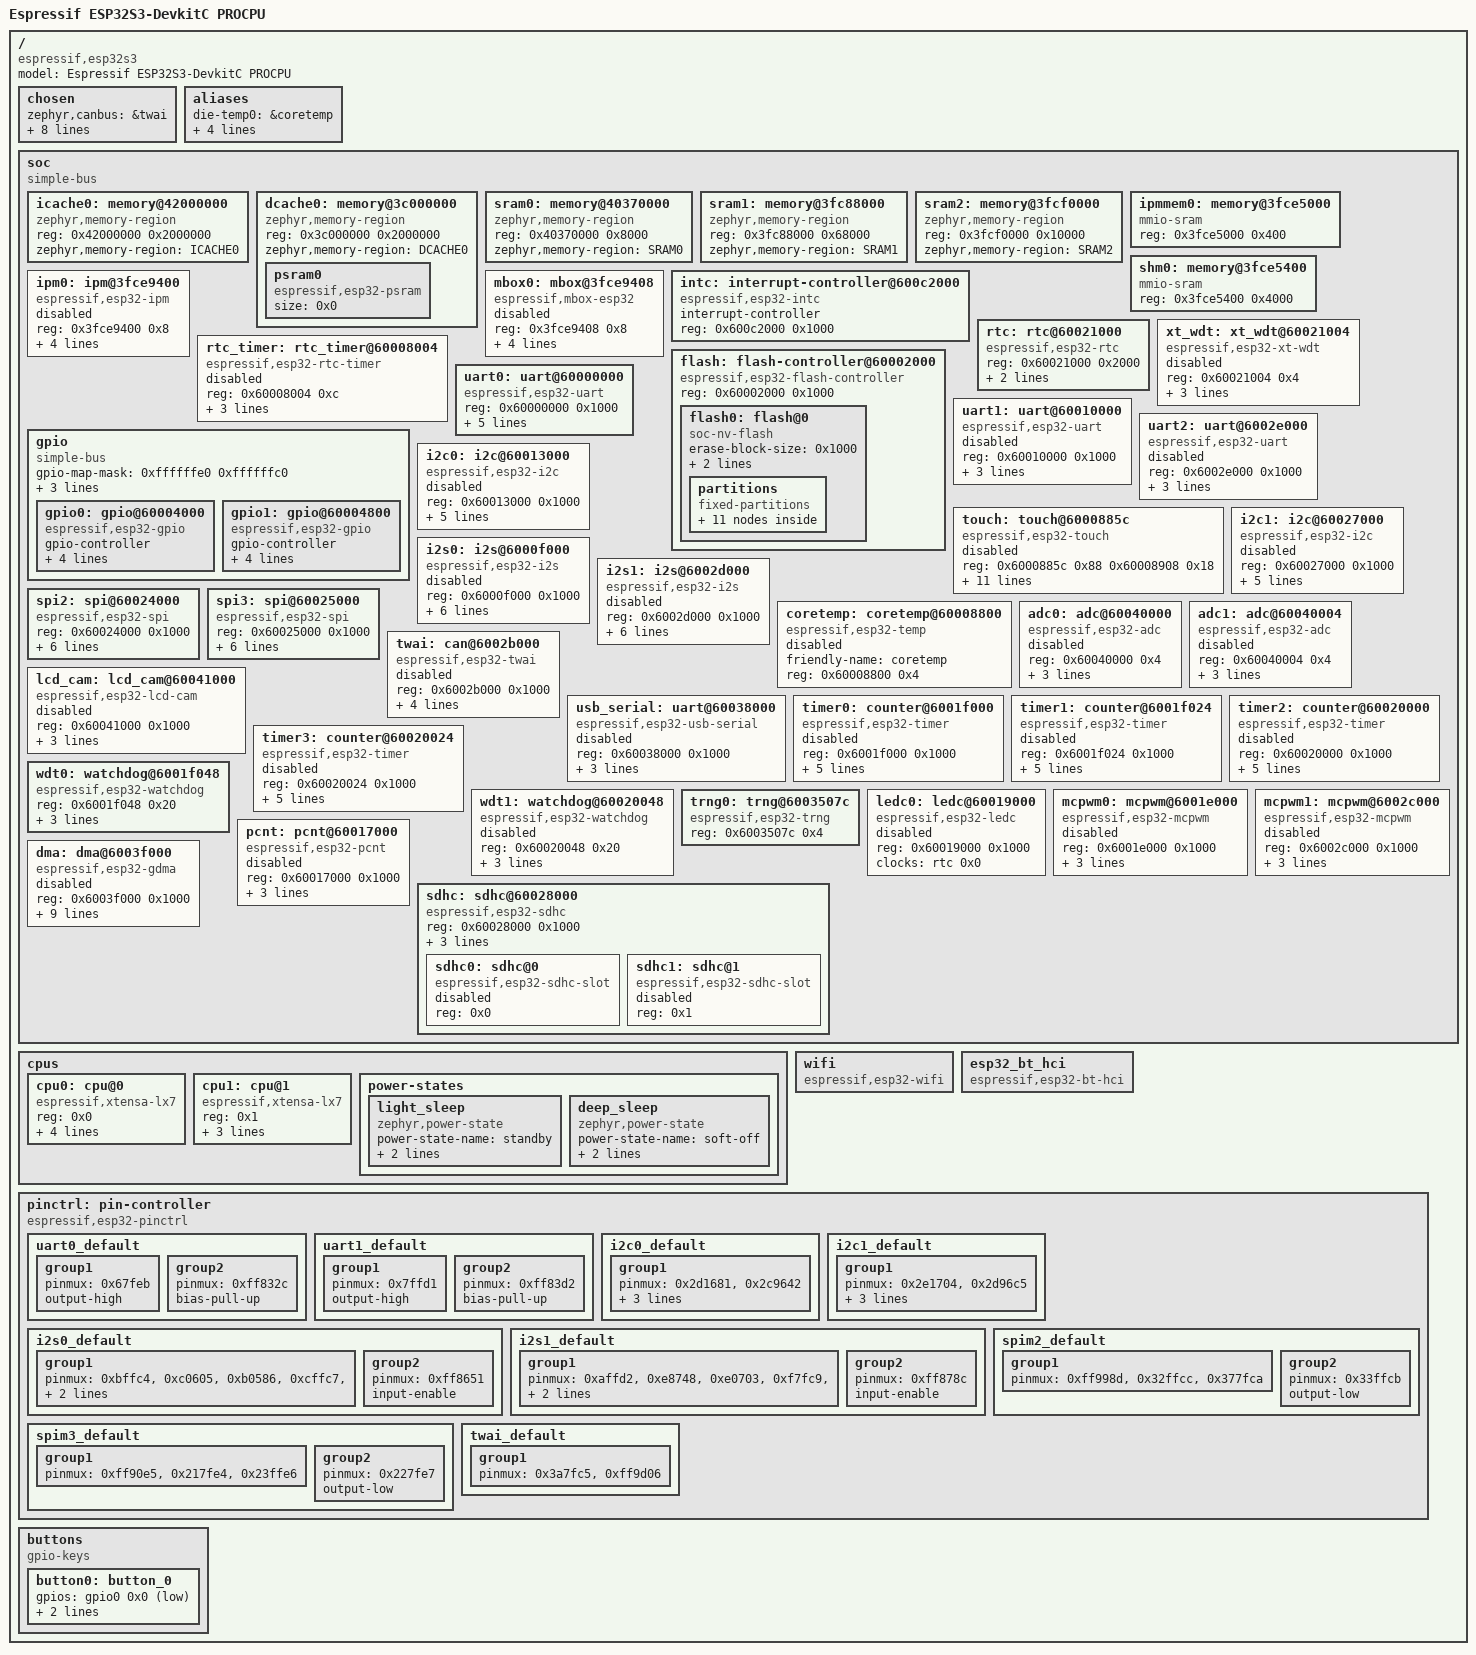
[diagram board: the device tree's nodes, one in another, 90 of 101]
/dts-v1/;

/* node '/' defined in zephyr/dts/common/skeleton.dtsi:9 */
/ {
	#address-cells = < 0x1 >;                   /* in zephyr/dts/common/skeleton.dtsi:10 */
	#size-cells = < 0x1 >;                      /* in zephyr/dts/common/skeleton.dtsi:11 */
	model = "Espressif ESP32S3-DevkitC PROCPU"; /* in zephyr/boards/espressif/esp32s3_devkitc/esp32s3_devkitc_procpu.dts:15 */
	compatible = "espressif,esp32s3";           /* in zephyr/boards/espressif/esp32s3_devkitc/esp32s3_devkitc_procpu.dts:16 */

	/* node '/chosen' defined in zephyr/dts/common/skeleton.dtsi:12 */
	chosen {
		zephyr,canbus = &twai;                    /* in zephyr/dts/xtensa/espressif/esp32s3/esp32s3_common.dtsi:23 */
		zephyr,entropy = &trng0;                  /* in zephyr/dts/xtensa/espressif/esp32s3/esp32s3_common.dtsi:24 */
		zephyr,flash-controller = &flash;         /* in zephyr/dts/xtensa/espressif/esp32s3/esp32s3_common.dtsi:25 */
		zephyr,sram = &sram1;                     /* in zephyr/boards/espressif/esp32s3_devkitc/esp32s3_devkitc_procpu.dts:24 */
		zephyr,console = &uart0;                  /* in zephyr/boards/espressif/esp32s3_devkitc/esp32s3_devkitc_procpu.dts:25 */
		zephyr,shell-uart = &uart0;               /* in zephyr/boards/espressif/esp32s3_devkitc/esp32s3_devkitc_procpu.dts:26 */
		zephyr,flash = &flash0;                   /* in zephyr/boards/espressif/esp32s3_devkitc/esp32s3_devkitc_procpu.dts:27 */
		zephyr,code-partition = &slot0_partition; /* in zephyr/boards/espressif/esp32s3_devkitc/esp32s3_devkitc_procpu.dts:28 */
		zephyr,bt-hci = &esp32_bt_hci;            /* in zephyr/boards/espressif/esp32s3_devkitc/esp32s3_devkitc_procpu.dts:29 */
	};

	/* node '/aliases' defined in zephyr/dts/common/skeleton.dtsi:13 */
	aliases {
		die-temp0 = &coretemp; /* in zephyr/dts/xtensa/espressif/esp32s3/esp32s3_common.dtsi:19 */
		i2c-0 = &i2c0;         /* in zephyr/boards/espressif/esp32s3_devkitc/esp32s3_devkitc_procpu.dts:19 */
		watchdog0 = &wdt0;     /* in zephyr/boards/espressif/esp32s3_devkitc/esp32s3_devkitc_procpu.dts:20 */
		uart-0 = &uart0;       /* in zephyr/boards/espressif/esp32s3_devkitc/esp32s3_devkitc_procpu.dts:33 */
		sw0 = &button0;        /* in zephyr/boards/espressif/esp32s3_devkitc/esp32s3_devkitc_procpu.dts:34 */
	};

	/* node '/soc' defined in zephyr/dts/xtensa/xtensa.dtsi:10 */
	soc {
		#address-cells = < 0x1 >;  /* in zephyr/dts/xtensa/espressif/esp32s3/esp32s3_common.dtsi:84 */
		#size-cells = < 0x1 >;     /* in zephyr/dts/xtensa/espressif/esp32s3/esp32s3_common.dtsi:85 */
		compatible = "simple-bus"; /* in zephyr/dts/xtensa/espressif/esp32s3/esp32s3_common.dtsi:86 */
		ranges;                    /* in zephyr/dts/xtensa/espressif/esp32s3/esp32s3_common.dtsi:87 */

		/* node '/soc/memory@42000000' defined in zephyr/dts/xtensa/espressif/esp32s3/esp32s3_common.dtsi:89 */
		icache0: memory@42000000 {
			compatible = "zephyr,memory-region"; /* in zephyr/dts/xtensa/espressif/esp32s3/esp32s3_common.dtsi:90 */
			reg = < 0x42000000 0x2000000 >;      /* in zephyr/dts/xtensa/espressif/esp32s3/esp32s3_common.dtsi:91 */
			zephyr,memory-region = "ICACHE0";    /* in zephyr/dts/xtensa/espressif/esp32s3/esp32s3_common.dtsi:92 */
		};

		/* node '/soc/memory@3c000000' defined in zephyr/dts/xtensa/espressif/esp32s3/esp32s3_common.dtsi:95 */
		dcache0: memory@3c000000 {
			compatible = "zephyr,memory-region"; /* in zephyr/dts/xtensa/espressif/esp32s3/esp32s3_common.dtsi:96 */
			reg = < 0x3c000000 0x2000000 >;      /* in zephyr/dts/xtensa/espressif/esp32s3/esp32s3_common.dtsi:97 */
			zephyr,memory-region = "DCACHE0";    /* in zephyr/dts/xtensa/espressif/esp32s3/esp32s3_common.dtsi:98 */

			/* node '/soc/memory@3c000000/psram0' defined in zephyr/dts/xtensa/espressif/esp32s3/esp32s3_common.dtsi:100 */
			psram0: psram0 {
				compatible = "espressif,esp32-psram"; /* in zephyr/dts/xtensa/espressif/esp32s3/esp32s3_common.dtsi:101 */
				size = < 0x0 >;                       /* in zephyr/dts/xtensa/espressif/esp32s3/esp32s3_common.dtsi:102 */
			};
		};

		/* node '/soc/memory@40370000' defined in zephyr/dts/xtensa/espressif/esp32s3/esp32s3_common.dtsi:106 */
		sram0: memory@40370000 {
			compatible = "zephyr,memory-region",
			             "mmio-sram";            /* in zephyr/dts/xtensa/espressif/esp32s3/esp32s3_common.dtsi:107 */
			reg = < 0x40370000 0x8000 >;         /* in zephyr/dts/xtensa/espressif/esp32s3/esp32s3_common.dtsi:108 */
			zephyr,memory-region = "SRAM0";      /* in zephyr/dts/xtensa/espressif/esp32s3/esp32s3_common.dtsi:109 */
		};

		/* node '/soc/memory@3fc88000' defined in zephyr/dts/xtensa/espressif/esp32s3/esp32s3_common.dtsi:112 */
		sram1: memory@3fc88000 {
			compatible = "zephyr,memory-region",
			             "mmio-sram";            /* in zephyr/dts/xtensa/espressif/esp32s3/esp32s3_common.dtsi:113 */
			reg = < 0x3fc88000 0x68000 >;        /* in zephyr/dts/xtensa/espressif/esp32s3/esp32s3_common.dtsi:114 */
			zephyr,memory-region = "SRAM1";      /* in zephyr/dts/xtensa/espressif/esp32s3/esp32s3_common.dtsi:115 */
		};

		/* node '/soc/memory@3fcf0000' defined in zephyr/dts/xtensa/espressif/esp32s3/esp32s3_common.dtsi:118 */
		sram2: memory@3fcf0000 {
			compatible = "zephyr,memory-region",
			             "mmio-sram";            /* in zephyr/dts/xtensa/espressif/esp32s3/esp32s3_common.dtsi:119 */
			reg = < 0x3fcf0000 0x10000 >;        /* in zephyr/dts/xtensa/espressif/esp32s3/esp32s3_common.dtsi:120 */
			zephyr,memory-region = "SRAM2";      /* in zephyr/dts/xtensa/espressif/esp32s3/esp32s3_common.dtsi:121 */
		};

		/* node '/soc/memory@3fce5000' defined in zephyr/dts/xtensa/espressif/esp32s3/esp32s3_common.dtsi:124 */
		ipmmem0: memory@3fce5000 {
			compatible = "mmio-sram";   /* in zephyr/dts/xtensa/espressif/esp32s3/esp32s3_common.dtsi:125 */
			reg = < 0x3fce5000 0x400 >; /* in zephyr/dts/xtensa/espressif/esp32s3/esp32s3_common.dtsi:126 */
			phandle = < 0x1 >;          /* in zephyr/dts/xtensa/espressif/esp32s3/esp32s3_common.dtsi:138 */
		};

		/* node '/soc/memory@3fce5400' defined in zephyr/dts/xtensa/espressif/esp32s3/esp32s3_common.dtsi:129 */
		shm0: memory@3fce5400 {
			compatible = "mmio-sram";    /* in zephyr/dts/xtensa/espressif/esp32s3/esp32s3_common.dtsi:130 */
			reg = < 0x3fce5400 0x4000 >; /* in zephyr/dts/xtensa/espressif/esp32s3/esp32s3_common.dtsi:131 */
		};

		/* node '/soc/ipm@3fce9400' defined in zephyr/dts/xtensa/espressif/esp32s3/esp32s3_common.dtsi:134 */
		ipm0: ipm@3fce9400 {
			compatible = "espressif,esp32-ipm"; /* in zephyr/dts/xtensa/espressif/esp32s3/esp32s3_common.dtsi:135 */
			reg = < 0x3fce9400 0x8 >;           /* in zephyr/dts/xtensa/espressif/esp32s3/esp32s3_common.dtsi:136 */
			status = "disabled";                /* in zephyr/dts/xtensa/espressif/esp32s3/esp32s3_common.dtsi:137 */
			shared-memory = < &ipmmem0 >;       /* in zephyr/dts/xtensa/espressif/esp32s3/esp32s3_common.dtsi:138 */
			shared-memory-size = < 0x400 >;     /* in zephyr/dts/xtensa/espressif/esp32s3/esp32s3_common.dtsi:139 */
			interrupts = < 0x4f 0x0 0x0 >,
			             < 0x50 0x0 0x0 >;      /* in zephyr/dts/xtensa/espressif/esp32s3/esp32s3_common.dtsi:140 */
			interrupt-parent = < &intc >;       /* in zephyr/dts/xtensa/espressif/esp32s3/esp32s3_common.dtsi:143 */
		};

		/* node '/soc/mbox@3fce9408' defined in zephyr/dts/xtensa/espressif/esp32s3/esp32s3_common.dtsi:146 */
		mbox0: mbox@3fce9408 {
			compatible = "espressif,mbox-esp32"; /* in zephyr/dts/xtensa/espressif/esp32s3/esp32s3_common.dtsi:147 */
			reg = < 0x3fce9408 0x8 >;            /* in zephyr/dts/xtensa/espressif/esp32s3/esp32s3_common.dtsi:148 */
			status = "disabled";                 /* in zephyr/dts/xtensa/espressif/esp32s3/esp32s3_common.dtsi:149 */
			shared-memory = < &ipmmem0 >;        /* in zephyr/dts/xtensa/espressif/esp32s3/esp32s3_common.dtsi:150 */
			shared-memory-size = < 0x400 >;      /* in zephyr/dts/xtensa/espressif/esp32s3/esp32s3_common.dtsi:151 */
			interrupts = < 0x4f 0x0 0x0 >,
			             < 0x50 0x0 0x0 >;       /* in zephyr/dts/xtensa/espressif/esp32s3/esp32s3_common.dtsi:152 */
			interrupt-parent = < &intc >;        /* in zephyr/dts/xtensa/espressif/esp32s3/esp32s3_common.dtsi:155 */
			#mbox-cells = < 0x1 >;               /* in zephyr/dts/xtensa/espressif/esp32s3/esp32s3_common.dtsi:156 */
		};

		/* node '/soc/interrupt-controller@600c2000' defined in zephyr/dts/xtensa/espressif/esp32s3/esp32s3_common.dtsi:159 */
		intc: interrupt-controller@600c2000 {
			#interrupt-cells = < 0x3 >;          /* in zephyr/dts/xtensa/espressif/esp32s3/esp32s3_common.dtsi:160 */
			#address-cells = < 0x0 >;            /* in zephyr/dts/xtensa/espressif/esp32s3/esp32s3_common.dtsi:161 */
			compatible = "espressif,esp32-intc"; /* in zephyr/dts/xtensa/espressif/esp32s3/esp32s3_common.dtsi:162 */
			interrupt-controller;                /* in zephyr/dts/xtensa/espressif/esp32s3/esp32s3_common.dtsi:163 */
			reg = < 0x600c2000 0x1000 >;         /* in zephyr/dts/xtensa/espressif/esp32s3/esp32s3_common.dtsi:164 */
			status = "okay";                     /* in zephyr/dts/xtensa/espressif/esp32s3/esp32s3_common.dtsi:165 */
			phandle = < 0x2 >;                   /* in zephyr/dts/xtensa/espressif/esp32s3/esp32s3_common.dtsi:143 */
		};

		/* node '/soc/rtc@60021000' defined in zephyr/dts/xtensa/espressif/esp32s3/esp32s3_common.dtsi:168 */
		rtc: rtc@60021000 {
			compatible = "espressif,esp32-rtc"; /* in zephyr/dts/xtensa/espressif/esp32s3/esp32s3_common.dtsi:169 */
			reg = < 0x60021000 0x2000 >;        /* in zephyr/dts/xtensa/espressif/esp32s3/esp32s3_common.dtsi:170 */
			fast-clk-src = < 0x1 >;             /* in zephyr/dts/xtensa/espressif/esp32s3/esp32s3_common.dtsi:171 */
			slow-clk-src = < 0x0 >;             /* in zephyr/dts/xtensa/espressif/esp32s3/esp32s3_common.dtsi:172 */
			#clock-cells = < 0x1 >;             /* in zephyr/dts/xtensa/espressif/esp32s3/esp32s3_common.dtsi:173 */
			status = "okay";                    /* in zephyr/dts/xtensa/espressif/esp32s3/esp32s3_common.dtsi:174 */
			phandle = < 0x3 >;                  /* in zephyr/dts/xtensa/espressif/esp32s3/esp32s3_common.dtsi:180 */
		};

		/* node '/soc/xt_wdt@60021004' defined in zephyr/dts/xtensa/espressif/esp32s3/esp32s3_common.dtsi:177 */
		xt_wdt: xt_wdt@60021004 {
			compatible = "espressif,esp32-xt-wdt"; /* in zephyr/dts/xtensa/espressif/esp32s3/esp32s3_common.dtsi:178 */
			reg = < 0x60021004 0x4 >;              /* in zephyr/dts/xtensa/espressif/esp32s3/esp32s3_common.dtsi:179 */
			clocks = < &rtc 0x28 >;                /* in zephyr/dts/xtensa/espressif/esp32s3/esp32s3_common.dtsi:180 */
			interrupts = < 0x27 0x0 0x0 >;         /* in zephyr/dts/xtensa/espressif/esp32s3/esp32s3_common.dtsi:181 */
			interrupt-parent = < &intc >;          /* in zephyr/dts/xtensa/espressif/esp32s3/esp32s3_common.dtsi:182 */
			status = "disabled";                   /* in zephyr/dts/xtensa/espressif/esp32s3/esp32s3_common.dtsi:183 */
		};

		/* node '/soc/rtc_timer@60008004' defined in zephyr/dts/xtensa/espressif/esp32s3/esp32s3_common.dtsi:186 */
		rtc_timer: rtc_timer@60008004 {
			reg = < 0x60008004 0xc >;                 /* in zephyr/dts/xtensa/espressif/esp32s3/esp32s3_common.dtsi:187 */
			compatible = "espressif,esp32-rtc-timer"; /* in zephyr/dts/xtensa/espressif/esp32s3/esp32s3_common.dtsi:188 */
			clocks = < &rtc 0x28 >;                   /* in zephyr/dts/xtensa/espressif/esp32s3/esp32s3_common.dtsi:189 */
			interrupts = < 0x27 0x0 0x0 >;            /* in zephyr/dts/xtensa/espressif/esp32s3/esp32s3_common.dtsi:190 */
			interrupt-parent = < &intc >;             /* in zephyr/dts/xtensa/espressif/esp32s3/esp32s3_common.dtsi:191 */
			status = "disabled";                      /* in zephyr/dts/xtensa/espressif/esp32s3/esp32s3_common.dtsi:192 */
		};

		/* node '/soc/flash-controller@60002000' defined in zephyr/dts/xtensa/espressif/esp32s3/esp32s3_common.dtsi:195 */
		flash: flash-controller@60002000 {
			compatible = "espressif,esp32-flash-controller"; /* in zephyr/dts/xtensa/espressif/esp32s3/esp32s3_common.dtsi:196 */
			reg = < 0x60002000 0x1000 >;                     /* in zephyr/dts/xtensa/espressif/esp32s3/esp32s3_common.dtsi:197 */
			#address-cells = < 0x1 >;                        /* in zephyr/dts/xtensa/espressif/esp32s3/esp32s3_common.dtsi:198 */
			#size-cells = < 0x1 >;                           /* in zephyr/dts/xtensa/espressif/esp32s3/esp32s3_common.dtsi:199 */

			/* node '/soc/flash-controller@60002000/flash@0' defined in zephyr/dts/xtensa/espressif/esp32s3/esp32s3_common.dtsi:201 */
			flash0: flash@0 {
				compatible = "soc-nv-flash";   /* in zephyr/dts/xtensa/espressif/esp32s3/esp32s3_common.dtsi:202 */
				erase-block-size = < 0x1000 >; /* in zephyr/dts/xtensa/espressif/esp32s3/esp32s3_common.dtsi:203 */
				write-block-size = < 0x4 >;    /* in zephyr/dts/xtensa/espressif/esp32s3/esp32s3_common.dtsi:204 */
				reg = < 0x0 0x800000 >;        /* in zephyr/dts/xtensa/espressif/esp32s3/esp32s3_wroom_n8.dtsi:11 */

				/* node '/soc/flash-controller@60002000/flash@0/partitions' defined in zephyr/dts/vendor/espressif/partitions_0x0_amp_4M.dtsi:8 */
				partitions {
					compatible = "fixed-partitions"; /* in zephyr/dts/vendor/espressif/partitions_0x0_amp_4M.dtsi:9 */
					#address-cells = < 0x1 >;        /* in zephyr/dts/vendor/espressif/partitions_0x0_amp_4M.dtsi:10 */
					#size-cells = < 0x1 >;           /* in zephyr/dts/vendor/espressif/partitions_0x0_amp_4M.dtsi:11 */

					/* node '/soc/flash-controller@60002000/flash@0/partitions/partition@0' defined in zephyr/dts/vendor/espressif/partitions_0x0_amp_4M.dtsi:13 */
					boot_partition: partition@0 {
						label = "mcuboot";     /* in zephyr/dts/vendor/espressif/partitions_0x0_amp_4M.dtsi:14 */
						reg = < 0x0 0x10000 >; /* in zephyr/dts/vendor/espressif/partitions_0x0_amp_4M.dtsi:15 */
					};

					/* node '/soc/flash-controller@60002000/flash@0/partitions/partition@10000' defined in zephyr/dts/vendor/espressif/partitions_0x0_amp_4M.dtsi:18 */
					sys_partition: partition@10000 {
						label = "sys";             /* in zephyr/dts/vendor/espressif/partitions_0x0_amp_4M.dtsi:19 */
						reg = < 0x10000 0x10000 >; /* in zephyr/dts/vendor/espressif/partitions_0x0_amp_4M.dtsi:20 */
					};

					/* node '/soc/flash-controller@60002000/flash@0/partitions/partition@20000' defined in zephyr/dts/vendor/espressif/partitions_0x0_amp_4M.dtsi:23 */
					slot0_partition: partition@20000 {
						label = "image-0";          /* in zephyr/dts/vendor/espressif/partitions_0x0_amp_4M.dtsi:24 */
						reg = < 0x20000 0x150000 >; /* in zephyr/dts/vendor/espressif/partitions_0x0_amp_4M.dtsi:25 */
					};

					/* node '/soc/flash-controller@60002000/flash@0/partitions/partition@170000' defined in zephyr/dts/vendor/espressif/partitions_0x0_amp_4M.dtsi:28 */
					slot1_partition: partition@170000 {
						label = "image-1";           /* in zephyr/dts/vendor/espressif/partitions_0x0_amp_4M.dtsi:29 */
						reg = < 0x170000 0x150000 >; /* in zephyr/dts/vendor/espressif/partitions_0x0_amp_4M.dtsi:30 */
					};

					/* node '/soc/flash-controller@60002000/flash@0/partitions/partition@2c0000' defined in zephyr/dts/vendor/espressif/partitions_0x0_amp_4M.dtsi:33 */
					slot0_appcpu_partition: partition@2c0000 {
						label = "image-0-appcpu";   /* in zephyr/dts/vendor/espressif/partitions_0x0_amp_4M.dtsi:34 */
						reg = < 0x2c0000 0x70000 >; /* in zephyr/dts/vendor/espressif/partitions_0x0_amp_4M.dtsi:35 */
					};

					/* node '/soc/flash-controller@60002000/flash@0/partitions/partition@330000' defined in zephyr/dts/vendor/espressif/partitions_0x0_amp_4M.dtsi:38 */
					slot1_appcpu_partition: partition@330000 {
						label = "image-1-appcpu";   /* in zephyr/dts/vendor/espressif/partitions_0x0_amp_4M.dtsi:39 */
						reg = < 0x330000 0x70000 >; /* in zephyr/dts/vendor/espressif/partitions_0x0_amp_4M.dtsi:40 */
					};

					/* node '/soc/flash-controller@60002000/flash@0/partitions/partition@3a0000' defined in zephyr/dts/vendor/espressif/partitions_0x0_amp_4M.dtsi:43 */
					slot0_lpcore_partition: partition@3a0000 {
						label = "image-0-lpcore";  /* in zephyr/dts/vendor/espressif/partitions_0x0_amp_4M.dtsi:44 */
						reg = < 0x3a0000 0x8000 >; /* in zephyr/dts/vendor/espressif/partitions_0x0_amp_4M.dtsi:45 */
					};

					/* node '/soc/flash-controller@60002000/flash@0/partitions/partition@3a8000' defined in zephyr/dts/vendor/espressif/partitions_0x0_amp_4M.dtsi:48 */
					slot1_lpcore_partition: partition@3a8000 {
						label = "image-1-lpcore";  /* in zephyr/dts/vendor/espressif/partitions_0x0_amp_4M.dtsi:49 */
						reg = < 0x3a8000 0x8000 >; /* in zephyr/dts/vendor/espressif/partitions_0x0_amp_4M.dtsi:50 */
					};

					/* node '/soc/flash-controller@60002000/flash@0/partitions/partition@3b0000' defined in zephyr/dts/vendor/espressif/partitions_0x0_amp_4M.dtsi:53 */
					storage_partition: partition@3b0000 {
						label = "storage";          /* in zephyr/dts/vendor/espressif/partitions_0x0_amp_4M.dtsi:54 */
						reg = < 0x3b0000 0x30000 >; /* in zephyr/dts/vendor/espressif/partitions_0x0_amp_4M.dtsi:55 */
					};

					/* node '/soc/flash-controller@60002000/flash@0/partitions/partition@3e0000' defined in zephyr/dts/vendor/espressif/partitions_0x0_amp_4M.dtsi:58 */
					scratch_partition: partition@3e0000 {
						label = "image-scratch";    /* in zephyr/dts/vendor/espressif/partitions_0x0_amp_4M.dtsi:59 */
						reg = < 0x3e0000 0x1f000 >; /* in zephyr/dts/vendor/espressif/partitions_0x0_amp_4M.dtsi:60 */
					};

					/* node '/soc/flash-controller@60002000/flash@0/partitions/partition@3ff000' defined in zephyr/dts/vendor/espressif/partitions_0x0_amp_4M.dtsi:63 */
					coredump_partition: partition@3ff000 {
						label = "coredump";        /* in zephyr/dts/vendor/espressif/partitions_0x0_amp_4M.dtsi:64 */
						reg = < 0x3ff000 0x1000 >; /* in zephyr/dts/vendor/espressif/partitions_0x0_amp_4M.dtsi:65 */
					};
				};
			};
		};

		/* node '/soc/uart@60000000' defined in zephyr/dts/xtensa/espressif/esp32s3/esp32s3_common.dtsi:209 */
		uart0: uart@60000000 {
			compatible = "espressif,esp32-uart"; /* in zephyr/dts/xtensa/espressif/esp32s3/esp32s3_common.dtsi:210 */
			reg = < 0x60000000 0x1000 >;         /* in zephyr/dts/xtensa/espressif/esp32s3/esp32s3_common.dtsi:211 */
			interrupts = < 0x1b 0x0 0x0 >;       /* in zephyr/dts/xtensa/espressif/esp32s3/esp32s3_common.dtsi:212 */
			interrupt-parent = < &intc >;        /* in zephyr/dts/xtensa/espressif/esp32s3/esp32s3_common.dtsi:213 */
			clocks = < &rtc 0x1 >;               /* in zephyr/dts/xtensa/espressif/esp32s3/esp32s3_common.dtsi:214 */
			status = "okay";                     /* in zephyr/boards/espressif/esp32s3_devkitc/esp32s3_devkitc_procpu.dts:52 */
			current-speed = < 0x1c200 >;         /* in zephyr/boards/espressif/esp32s3_devkitc/esp32s3_devkitc_procpu.dts:53 */
			pinctrl-0 = < &uart0_default >;      /* in zephyr/boards/espressif/esp32s3_devkitc/esp32s3_devkitc_procpu.dts:54 */
			pinctrl-names = "default";           /* in zephyr/boards/espressif/esp32s3_devkitc/esp32s3_devkitc_procpu.dts:55 */
		};

		/* node '/soc/uart@60010000' defined in zephyr/dts/xtensa/espressif/esp32s3/esp32s3_common.dtsi:218 */
		uart1: uart@60010000 {
			compatible = "espressif,esp32-uart"; /* in zephyr/dts/xtensa/espressif/esp32s3/esp32s3_common.dtsi:219 */
			reg = < 0x60010000 0x1000 >;         /* in zephyr/dts/xtensa/espressif/esp32s3/esp32s3_common.dtsi:220 */
			interrupts = < 0x1c 0x0 0x0 >;       /* in zephyr/dts/xtensa/espressif/esp32s3/esp32s3_common.dtsi:221 */
			interrupt-parent = < &intc >;        /* in zephyr/dts/xtensa/espressif/esp32s3/esp32s3_common.dtsi:222 */
			clocks = < &rtc 0x2 >;               /* in zephyr/dts/xtensa/espressif/esp32s3/esp32s3_common.dtsi:223 */
			status = "disabled";                 /* in zephyr/dts/xtensa/espressif/esp32s3/esp32s3_common.dtsi:224 */
		};

		/* node '/soc/uart@6002e000' defined in zephyr/dts/xtensa/espressif/esp32s3/esp32s3_common.dtsi:227 */
		uart2: uart@6002e000 {
			compatible = "espressif,esp32-uart"; /* in zephyr/dts/xtensa/espressif/esp32s3/esp32s3_common.dtsi:228 */
			reg = < 0x6002e000 0x1000 >;         /* in zephyr/dts/xtensa/espressif/esp32s3/esp32s3_common.dtsi:229 */
			interrupts = < 0x1d 0x0 0x0 >;       /* in zephyr/dts/xtensa/espressif/esp32s3/esp32s3_common.dtsi:230 */
			interrupt-parent = < &intc >;        /* in zephyr/dts/xtensa/espressif/esp32s3/esp32s3_common.dtsi:231 */
			clocks = < &rtc 0x3 >;               /* in zephyr/dts/xtensa/espressif/esp32s3/esp32s3_common.dtsi:232 */
			status = "disabled";                 /* in zephyr/dts/xtensa/espressif/esp32s3/esp32s3_common.dtsi:233 */
		};

		/* node '/soc/gpio' defined in zephyr/dts/xtensa/espressif/esp32s3/esp32s3_common.dtsi:236 */
		gpio: gpio {
			compatible = "simple-bus";                                     /* in zephyr/dts/xtensa/espressif/esp32s3/esp32s3_common.dtsi:237 */
			gpio-map-mask = < 0xffffffe0 0xffffffc0 >;                     /* in zephyr/dts/xtensa/espressif/esp32s3/esp32s3_common.dtsi:238 */
			gpio-map-pass-thru = < 0x1f 0x3f >;                            /* in zephyr/dts/xtensa/espressif/esp32s3/esp32s3_common.dtsi:239 */
			gpio-map = < 0x0 0x0 &gpio0 0x0 0x0 0x20 0x0 &gpio1 0x0 0x0 >; /* in zephyr/dts/xtensa/espressif/esp32s3/esp32s3_common.dtsi:240 */
			#gpio-cells = < 0x2 >;                                         /* in zephyr/dts/xtensa/espressif/esp32s3/esp32s3_common.dtsi:244 */
			#address-cells = < 0x1 >;                                      /* in zephyr/dts/xtensa/espressif/esp32s3/esp32s3_common.dtsi:245 */
			#size-cells = < 0x1 >;                                         /* in zephyr/dts/xtensa/espressif/esp32s3/esp32s3_common.dtsi:246 */
			ranges;                                                        /* in zephyr/dts/xtensa/espressif/esp32s3/esp32s3_common.dtsi:247 */

			/* node '/soc/gpio/gpio@60004000' defined in zephyr/dts/xtensa/espressif/esp32s3/esp32s3_common.dtsi:249 */
			gpio0: gpio@60004000 {
				compatible = "espressif,esp32-gpio"; /* in zephyr/dts/xtensa/espressif/esp32s3/esp32s3_common.dtsi:250 */
				gpio-controller;                     /* in zephyr/dts/xtensa/espressif/esp32s3/esp32s3_common.dtsi:251 */
				#gpio-cells = < 0x2 >;               /* in zephyr/dts/xtensa/espressif/esp32s3/esp32s3_common.dtsi:252 */
				reg = < 0x60004000 0x800 >;          /* in zephyr/dts/xtensa/espressif/esp32s3/esp32s3_common.dtsi:253 */
				interrupts = < 0x10 0x0 0x0 >;       /* in zephyr/dts/xtensa/espressif/esp32s3/esp32s3_common.dtsi:254 */
				interrupt-parent = < &intc >;        /* in zephyr/dts/xtensa/espressif/esp32s3/esp32s3_common.dtsi:255 */
				ngpios = < 0x20 >;                   /* in zephyr/dts/xtensa/espressif/esp32s3/esp32s3_common.dtsi:261 */
				status = "okay";                     /* in zephyr/boards/espressif/esp32s3_devkitc/esp32s3_devkitc_procpu.dts:59 */
				phandle = < 0x5 >;                   /* in zephyr/dts/xtensa/espressif/esp32s3/esp32s3_common.dtsi:240 */
			};

			/* node '/soc/gpio/gpio@60004800' defined in zephyr/dts/xtensa/espressif/esp32s3/esp32s3_common.dtsi:264 */
			gpio1: gpio@60004800 {
				compatible = "espressif,esp32-gpio"; /* in zephyr/dts/xtensa/espressif/esp32s3/esp32s3_common.dtsi:265 */
				gpio-controller;                     /* in zephyr/dts/xtensa/espressif/esp32s3/esp32s3_common.dtsi:266 */
				#gpio-cells = < 0x2 >;               /* in zephyr/dts/xtensa/espressif/esp32s3/esp32s3_common.dtsi:267 */
				reg = < 0x60004800 0x800 >;          /* in zephyr/dts/xtensa/espressif/esp32s3/esp32s3_common.dtsi:268 */
				interrupts = < 0x10 0x0 0x0 >;       /* in zephyr/dts/xtensa/espressif/esp32s3/esp32s3_common.dtsi:269 */
				interrupt-parent = < &intc >;        /* in zephyr/dts/xtensa/espressif/esp32s3/esp32s3_common.dtsi:270 */
				ngpios = < 0x16 >;                   /* in zephyr/dts/xtensa/espressif/esp32s3/esp32s3_common.dtsi:271 */
				status = "okay";                     /* in zephyr/boards/espressif/esp32s3_devkitc/esp32s3_devkitc_procpu.dts:63 */
				phandle = < 0x6 >;                   /* in zephyr/dts/xtensa/espressif/esp32s3/esp32s3_common.dtsi:240 */
			};
		};

		/* node '/soc/touch@6000885c' defined in zephyr/dts/xtensa/espressif/esp32s3/esp32s3_common.dtsi:275 */
		touch: touch@6000885c {
			compatible = "espressif,esp32-touch";      /* in zephyr/dts/xtensa/espressif/esp32s3/esp32s3_common.dtsi:276 */
			reg = < 0x6000885c 0x88 0x60008908 0x18 >; /* in zephyr/dts/xtensa/espressif/esp32s3/esp32s3_common.dtsi:277 */
			interrupts = < 0x27 0x0 0x0 >;             /* in zephyr/dts/xtensa/espressif/esp32s3/esp32s3_common.dtsi:278 */
			interrupt-parent = < &intc >;              /* in zephyr/dts/xtensa/espressif/esp32s3/esp32s3_common.dtsi:279 */
			status = "disabled";                       /* in zephyr/dts/xtensa/espressif/esp32s3/esp32s3_common.dtsi:280 */
			debounce-interval-ms = < 0x1e >;           /* in zephyr/boards/espressif/esp32s3_devkitc/esp32s3_devkitc_procpu.dts:67 */
			href-microvolt = < 0x2932e0 >;             /* in zephyr/boards/espressif/esp32s3_devkitc/esp32s3_devkitc_procpu.dts:68 */
			lref-microvolt = < 0x7a120 >;              /* in zephyr/boards/espressif/esp32s3_devkitc/esp32s3_devkitc_procpu.dts:69 */
			href-atten-microvolt = < 0xf4240 >;        /* in zephyr/boards/espressif/esp32s3_devkitc/esp32s3_devkitc_procpu.dts:70 */
			filter-mode = < 0x2 >;                     /* in zephyr/boards/espressif/esp32s3_devkitc/esp32s3_devkitc_procpu.dts:71 */
			filter-debounce-cnt = < 0x1 >;             /* in zephyr/boards/espressif/esp32s3_devkitc/esp32s3_devkitc_procpu.dts:72 */
			filter-noise-thr = < 0x0 >;                /* in zephyr/boards/espressif/esp32s3_devkitc/esp32s3_devkitc_procpu.dts:73 */
			filter-jitter-step = < 0x4 >;              /* in zephyr/boards/espressif/esp32s3_devkitc/esp32s3_devkitc_procpu.dts:74 */
			filter-smooth-level = < 0x1 >;             /* in zephyr/boards/espressif/esp32s3_devkitc/esp32s3_devkitc_procpu.dts:75 */
		};

		/* node '/soc/i2c@60013000' defined in zephyr/dts/xtensa/espressif/esp32s3/esp32s3_common.dtsi:283 */
		i2c0: i2c@60013000 {
			compatible = "espressif,esp32-i2c"; /* in zephyr/dts/xtensa/espressif/esp32s3/esp32s3_common.dtsi:284 */
			#address-cells = < 0x1 >;           /* in zephyr/dts/xtensa/espressif/esp32s3/esp32s3_common.dtsi:285 */
			#size-cells = < 0x0 >;              /* in zephyr/dts/xtensa/espressif/esp32s3/esp32s3_common.dtsi:286 */
			reg = < 0x60013000 0x1000 >;        /* in zephyr/dts/xtensa/espressif/esp32s3/esp32s3_common.dtsi:287 */
			interrupts = < 0x2a 0x0 0x0 >;      /* in zephyr/dts/xtensa/espressif/esp32s3/esp32s3_common.dtsi:288 */
			interrupt-parent = < &intc >;       /* in zephyr/dts/xtensa/espressif/esp32s3/esp32s3_common.dtsi:289 */
			clocks = < &rtc 0x5 >;              /* in zephyr/dts/xtensa/espressif/esp32s3/esp32s3_common.dtsi:290 */
			status = "disabled";                /* in zephyr/dts/xtensa/espressif/esp32s3/esp32s3_common.dtsi:291 */
			clock-frequency = < 0x186a0 >;      /* in zephyr/boards/espressif/esp32s3_devkitc/esp32s3_devkitc_procpu.dts:79 */
			pinctrl-0 = < &i2c0_default >;      /* in zephyr/boards/espressif/esp32s3_devkitc/esp32s3_devkitc_procpu.dts:80 */
			pinctrl-names = "default";          /* in zephyr/boards/espressif/esp32s3_devkitc/esp32s3_devkitc_procpu.dts:81 */
		};

		/* node '/soc/i2c@60027000' defined in zephyr/dts/xtensa/espressif/esp32s3/esp32s3_common.dtsi:294 */
		i2c1: i2c@60027000 {
			compatible = "espressif,esp32-i2c"; /* in zephyr/dts/xtensa/espressif/esp32s3/esp32s3_common.dtsi:295 */
			#address-cells = < 0x1 >;           /* in zephyr/dts/xtensa/espressif/esp32s3/esp32s3_common.dtsi:296 */
			#size-cells = < 0x0 >;              /* in zephyr/dts/xtensa/espressif/esp32s3/esp32s3_common.dtsi:297 */
			reg = < 0x60027000 0x1000 >;        /* in zephyr/dts/xtensa/espressif/esp32s3/esp32s3_common.dtsi:298 */
			interrupts = < 0x2b 0x0 0x0 >;      /* in zephyr/dts/xtensa/espressif/esp32s3/esp32s3_common.dtsi:299 */
			interrupt-parent = < &intc >;       /* in zephyr/dts/xtensa/espressif/esp32s3/esp32s3_common.dtsi:300 */
			clocks = < &rtc 0x6 >;              /* in zephyr/dts/xtensa/espressif/esp32s3/esp32s3_common.dtsi:301 */
			status = "disabled";                /* in zephyr/dts/xtensa/espressif/esp32s3/esp32s3_common.dtsi:302 */
			clock-frequency = < 0x186a0 >;      /* in zephyr/boards/espressif/esp32s3_devkitc/esp32s3_devkitc_procpu.dts:85 */
			pinctrl-0 = < &i2c1_default >;      /* in zephyr/boards/espressif/esp32s3_devkitc/esp32s3_devkitc_procpu.dts:86 */
			pinctrl-names = "default";          /* in zephyr/boards/espressif/esp32s3_devkitc/esp32s3_devkitc_procpu.dts:87 */
		};

		/* node '/soc/i2s@6000f000' defined in zephyr/dts/xtensa/espressif/esp32s3/esp32s3_common.dtsi:305 */
		i2s0: i2s@6000f000 {
			compatible = "espressif,esp32-i2s"; /* in zephyr/dts/xtensa/espressif/esp32s3/esp32s3_common.dtsi:306 */
			#address-cells = < 0x1 >;           /* in zephyr/dts/xtensa/espressif/esp32s3/esp32s3_common.dtsi:307 */
			#size-cells = < 0x0 >;              /* in zephyr/dts/xtensa/espressif/esp32s3/esp32s3_common.dtsi:308 */
			reg = < 0x6000f000 0x1000 >;        /* in zephyr/dts/xtensa/espressif/esp32s3/esp32s3_common.dtsi:309 */
			interrupts = < 0x19 0x0 0x0 >;      /* in zephyr/dts/xtensa/espressif/esp32s3/esp32s3_common.dtsi:310 */
			interrupt-parent = < &intc >;       /* in zephyr/dts/xtensa/espressif/esp32s3/esp32s3_common.dtsi:311 */
			clocks = < &rtc 0x7 >;              /* in zephyr/dts/xtensa/espressif/esp32s3/esp32s3_common.dtsi:312 */
			dmas = < &dma 0x2 >,
			       < &dma 0x3 >;                /* in zephyr/dts/xtensa/espressif/esp32s3/esp32s3_common.dtsi:313 */
			dma-names = "rx",
			            "tx";                   /* in zephyr/dts/xtensa/espressif/esp32s3/esp32s3_common.dtsi:314 */
			unit = < 0x0 >;                     /* in zephyr/dts/xtensa/espressif/esp32s3/esp32s3_common.dtsi:315 */
			status = "disabled";                /* in zephyr/boards/espressif/esp32s3_devkitc/esp32s3_devkitc_procpu.dts:93 */
			pinctrl-0 = < &i2s0_default >;      /* in zephyr/boards/espressif/esp32s3_devkitc/esp32s3_devkitc_procpu.dts:91 */
			pinctrl-names = "default";          /* in zephyr/boards/espressif/esp32s3_devkitc/esp32s3_devkitc_procpu.dts:92 */
		};

		/* node '/soc/i2s@6002d000' defined in zephyr/dts/xtensa/espressif/esp32s3/esp32s3_common.dtsi:319 */
		i2s1: i2s@6002d000 {
			compatible = "espressif,esp32-i2s"; /* in zephyr/dts/xtensa/espressif/esp32s3/esp32s3_common.dtsi:320 */
			#address-cells = < 0x1 >;           /* in zephyr/dts/xtensa/espressif/esp32s3/esp32s3_common.dtsi:321 */
			#size-cells = < 0x0 >;              /* in zephyr/dts/xtensa/espressif/esp32s3/esp32s3_common.dtsi:322 */
			reg = < 0x6002d000 0x1000 >;        /* in zephyr/dts/xtensa/espressif/esp32s3/esp32s3_common.dtsi:323 */
			interrupts = < 0x1a 0x0 0x0 >;      /* in zephyr/dts/xtensa/espressif/esp32s3/esp32s3_common.dtsi:324 */
			interrupt-parent = < &intc >;       /* in zephyr/dts/xtensa/espressif/esp32s3/esp32s3_common.dtsi:325 */
			clocks = < &rtc 0x8 >;              /* in zephyr/dts/xtensa/espressif/esp32s3/esp32s3_common.dtsi:326 */
			dmas = < &dma 0x4 >,
			       < &dma 0x5 >;                /* in zephyr/dts/xtensa/espressif/esp32s3/esp32s3_common.dtsi:327 */
			dma-names = "rx",
			            "tx";                   /* in zephyr/dts/xtensa/espressif/esp32s3/esp32s3_common.dtsi:328 */
			unit = < 0x1 >;                     /* in zephyr/dts/xtensa/espressif/esp32s3/esp32s3_common.dtsi:329 */
			status = "disabled";                /* in zephyr/boards/espressif/esp32s3_devkitc/esp32s3_devkitc_procpu.dts:99 */
			pinctrl-0 = < &i2s1_default >;      /* in zephyr/boards/espressif/esp32s3_devkitc/esp32s3_devkitc_procpu.dts:97 */
			pinctrl-names = "default";          /* in zephyr/boards/espressif/esp32s3_devkitc/esp32s3_devkitc_procpu.dts:98 */
		};

		/* node '/soc/spi@60024000' defined in zephyr/dts/xtensa/espressif/esp32s3/esp32s3_common.dtsi:333 */
		spi2: spi@60024000 {
			compatible = "espressif,esp32-spi"; /* in zephyr/dts/xtensa/espressif/esp32s3/esp32s3_common.dtsi:334 */
			reg = < 0x60024000 0x1000 >;        /* in zephyr/dts/xtensa/espressif/esp32s3/esp32s3_common.dtsi:335 */
			interrupts = < 0x15 0x0 0x0 >;      /* in zephyr/dts/xtensa/espressif/esp32s3/esp32s3_common.dtsi:336 */
			interrupt-parent = < &intc >;       /* in zephyr/dts/xtensa/espressif/esp32s3/esp32s3_common.dtsi:337 */
			clocks = < &rtc 0x15 >;             /* in zephyr/dts/xtensa/espressif/esp32s3/esp32s3_common.dtsi:338 */
			dma-clk = < 0x25 >;                 /* in zephyr/dts/xtensa/espressif/esp32s3/esp32s3_common.dtsi:339 */
			dma-host = < 0x0 >;                 /* in zephyr/dts/xtensa/espressif/esp32s3/esp32s3_common.dtsi:340 */
			status = "okay";                    /* in zephyr/boards/espressif/esp32s3_devkitc/esp32s3_devkitc_procpu.dts:105 */
			#address-cells = < 0x1 >;           /* in zephyr/boards/espressif/esp32s3_devkitc/esp32s3_devkitc_procpu.dts:103 */
			#size-cells = < 0x0 >;              /* in zephyr/boards/espressif/esp32s3_devkitc/esp32s3_devkitc_procpu.dts:104 */
			pinctrl-0 = < &spim2_default >;     /* in zephyr/boards/espressif/esp32s3_devkitc/esp32s3_devkitc_procpu.dts:106 */
			pinctrl-names = "default";          /* in zephyr/boards/espressif/esp32s3_devkitc/esp32s3_devkitc_procpu.dts:107 */
		};

		/* node '/soc/spi@60025000' defined in zephyr/dts/xtensa/espressif/esp32s3/esp32s3_common.dtsi:344 */
		spi3: spi@60025000 {
			compatible = "espressif,esp32-spi"; /* in zephyr/dts/xtensa/espressif/esp32s3/esp32s3_common.dtsi:345 */
			reg = < 0x60025000 0x1000 >;        /* in zephyr/dts/xtensa/espressif/esp32s3/esp32s3_common.dtsi:346 */
			interrupts = < 0x16 0x0 0x0 >;      /* in zephyr/dts/xtensa/espressif/esp32s3/esp32s3_common.dtsi:347 */
			interrupt-parent = < &intc >;       /* in zephyr/dts/xtensa/espressif/esp32s3/esp32s3_common.dtsi:348 */
			clocks = < &rtc 0x16 >;             /* in zephyr/dts/xtensa/espressif/esp32s3/esp32s3_common.dtsi:349 */
			dma-clk = < 0x25 >;                 /* in zephyr/dts/xtensa/espressif/esp32s3/esp32s3_common.dtsi:350 */
			dma-host = < 0x1 >;                 /* in zephyr/dts/xtensa/espressif/esp32s3/esp32s3_common.dtsi:351 */
			status = "okay";                    /* in zephyr/boards/espressif/esp32s3_devkitc/esp32s3_devkitc_procpu.dts:113 */
			#address-cells = < 0x1 >;           /* in zephyr/boards/espressif/esp32s3_devkitc/esp32s3_devkitc_procpu.dts:111 */
			#size-cells = < 0x0 >;              /* in zephyr/boards/espressif/esp32s3_devkitc/esp32s3_devkitc_procpu.dts:112 */
			pinctrl-0 = < &spim3_default >;     /* in zephyr/boards/espressif/esp32s3_devkitc/esp32s3_devkitc_procpu.dts:114 */
			pinctrl-names = "default";          /* in zephyr/boards/espressif/esp32s3_devkitc/esp32s3_devkitc_procpu.dts:115 */
		};

		/* node '/soc/coretemp@60008800' defined in zephyr/dts/xtensa/espressif/esp32s3/esp32s3_common.dtsi:355 */
		coretemp: coretemp@60008800 {
			compatible = "espressif,esp32-temp"; /* in zephyr/dts/xtensa/espressif/esp32s3/esp32s3_common.dtsi:356 */
			friendly-name = "coretemp";          /* in zephyr/dts/xtensa/espressif/esp32s3/esp32s3_common.dtsi:357 */
			reg = < 0x60008800 0x4 >;            /* in zephyr/dts/xtensa/espressif/esp32s3/esp32s3_common.dtsi:358 */
			status = "disabled";                 /* in zephyr/dts/xtensa/espressif/esp32s3/esp32s3_common.dtsi:359 */
		};

		/* node '/soc/adc@60040000' defined in zephyr/dts/xtensa/espressif/esp32s3/esp32s3_common.dtsi:362 */
		adc0: adc@60040000 {
			compatible = "espressif,esp32-adc"; /* in zephyr/dts/xtensa/espressif/esp32s3/esp32s3_common.dtsi:363 */
			reg = < 0x60040000 0x4 >;           /* in zephyr/dts/xtensa/espressif/esp32s3/esp32s3_common.dtsi:364 */
			clocks = < &rtc 0x27 >;             /* in zephyr/dts/xtensa/espressif/esp32s3/esp32s3_common.dtsi:365 */
			unit = < 0x1 >;                     /* in zephyr/dts/xtensa/espressif/esp32s3/esp32s3_common.dtsi:366 */
			channel-count = < 0xa >;            /* in zephyr/dts/xtensa/espressif/esp32s3/esp32s3_common.dtsi:367 */
			#io-channel-cells = < 0x1 >;        /* in zephyr/dts/xtensa/espressif/esp32s3/esp32s3_common.dtsi:368 */
			status = "disabled";                /* in zephyr/dts/xtensa/espressif/esp32s3/esp32s3_common.dtsi:369 */
		};

		/* node '/soc/adc@60040004' defined in zephyr/dts/xtensa/espressif/esp32s3/esp32s3_common.dtsi:372 */
		adc1: adc@60040004 {
			compatible = "espressif,esp32-adc"; /* in zephyr/dts/xtensa/espressif/esp32s3/esp32s3_common.dtsi:373 */
			reg = < 0x60040004 0x4 >;           /* in zephyr/dts/xtensa/espressif/esp32s3/esp32s3_common.dtsi:374 */
			clocks = < &rtc 0x27 >;             /* in zephyr/dts/xtensa/espressif/esp32s3/esp32s3_common.dtsi:375 */
			unit = < 0x2 >;                     /* in zephyr/dts/xtensa/espressif/esp32s3/esp32s3_common.dtsi:376 */
			channel-count = < 0xa >;            /* in zephyr/dts/xtensa/espressif/esp32s3/esp32s3_common.dtsi:377 */
			#io-channel-cells = < 0x1 >;        /* in zephyr/dts/xtensa/espressif/esp32s3/esp32s3_common.dtsi:378 */
			status = "disabled";                /* in zephyr/dts/xtensa/espressif/esp32s3/esp32s3_common.dtsi:379 */
		};

		/* node '/soc/can@6002b000' defined in zephyr/dts/xtensa/espressif/esp32s3/esp32s3_common.dtsi:382 */
		twai: can@6002b000 {
			compatible = "espressif,esp32-twai"; /* in zephyr/dts/xtensa/espressif/esp32s3/esp32s3_common.dtsi:383 */
			reg = < 0x6002b000 0x1000 >;         /* in zephyr/dts/xtensa/espressif/esp32s3/esp32s3_common.dtsi:384 */
			interrupts = < 0x25 0x0 0x0 >;       /* in zephyr/dts/xtensa/espressif/esp32s3/esp32s3_common.dtsi:385 */
			interrupt-parent = < &intc >;        /* in zephyr/dts/xtensa/espressif/esp32s3/esp32s3_common.dtsi:386 */
			clocks = < &rtc 0x18 >;              /* in zephyr/dts/xtensa/espressif/esp32s3/esp32s3_common.dtsi:387 */
			status = "disabled";                 /* in zephyr/dts/xtensa/espressif/esp32s3/esp32s3_common.dtsi:388 */
			pinctrl-0 = < &twai_default >;       /* in zephyr/boards/espressif/esp32s3_devkitc/esp32s3_devkitc_procpu.dts:119 */
			pinctrl-names = "default";           /* in zephyr/boards/espressif/esp32s3_devkitc/esp32s3_devkitc_procpu.dts:120 */
		};

		/* node '/soc/lcd_cam@60041000' defined in zephyr/dts/xtensa/espressif/esp32s3/esp32s3_common.dtsi:391 */
		lcd_cam: lcd_cam@60041000 {
			compatible = "espressif,esp32-lcd-cam"; /* in zephyr/dts/xtensa/espressif/esp32s3/esp32s3_common.dtsi:392 */
			reg = < 0x60041000 0x1000 >;            /* in zephyr/dts/xtensa/espressif/esp32s3/esp32s3_common.dtsi:393 */
			clocks = < &rtc 0x9 >;                  /* in zephyr/dts/xtensa/espressif/esp32s3/esp32s3_common.dtsi:394 */
			interrupts = < 0x18 0x0 0x0 >;          /* in zephyr/dts/xtensa/espressif/esp32s3/esp32s3_common.dtsi:395 */
			interrupt-parent = < &intc >;           /* in zephyr/dts/xtensa/espressif/esp32s3/esp32s3_common.dtsi:396 */
			status = "disabled";                    /* in zephyr/dts/xtensa/espressif/esp32s3/esp32s3_common.dtsi:397 */
		};

		/* node '/soc/uart@60038000' defined in zephyr/dts/xtensa/espressif/esp32s3/esp32s3_common.dtsi:400 */
		usb_serial: uart@60038000 {
			compatible = "espressif,esp32-usb-serial"; /* in zephyr/dts/xtensa/espressif/esp32s3/esp32s3_common.dtsi:401 */
			reg = < 0x60038000 0x1000 >;               /* in zephyr/dts/xtensa/espressif/esp32s3/esp32s3_common.dtsi:402 */
			status = "disabled";                       /* in zephyr/boards/espressif/esp32s3_devkitc/esp32s3_devkitc_procpu.dts:48 */
			interrupts = < 0x60 0x0 0x0 >;             /* in zephyr/dts/xtensa/espressif/esp32s3/esp32s3_common.dtsi:404 */
			interrupt-parent = < &intc >;              /* in zephyr/dts/xtensa/espressif/esp32s3/esp32s3_common.dtsi:405 */
			clocks = < &rtc 0x4 >;                     /* in zephyr/dts/xtensa/espressif/esp32s3/esp32s3_common.dtsi:406 */
		};

		/* node '/soc/counter@6001f000' defined in zephyr/dts/xtensa/espressif/esp32s3/esp32s3_common.dtsi:409 */
		timer0: counter@6001f000 {
			compatible = "espressif,esp32-timer"; /* in zephyr/dts/xtensa/espressif/esp32s3/esp32s3_common.dtsi:410 */
			reg = < 0x6001f000 0x1000 >;          /* in zephyr/dts/xtensa/espressif/esp32s3/esp32s3_common.dtsi:411 */
			clocks = < &rtc 0xa >;                /* in zephyr/dts/xtensa/espressif/esp32s3/esp32s3_common.dtsi:412 */
			group = < 0x0 >;                      /* in zephyr/dts/xtensa/espressif/esp32s3/esp32s3_common.dtsi:413 */
			index = < 0x0 >;                      /* in zephyr/dts/xtensa/espressif/esp32s3/esp32s3_common.dtsi:414 */
			interrupts = < 0x32 0x0 0x0 >;        /* in zephyr/dts/xtensa/espressif/esp32s3/esp32s3_common.dtsi:415 */
			interrupt-parent = < &intc >;         /* in zephyr/dts/xtensa/espressif/esp32s3/esp32s3_common.dtsi:416 */
			status = "disabled";                  /* in zephyr/boards/espressif/esp32s3_devkitc/esp32s3_devkitc_procpu.dts:124 */
		};

		/* node '/soc/counter@6001f024' defined in zephyr/dts/xtensa/espressif/esp32s3/esp32s3_common.dtsi:420 */
		timer1: counter@6001f024 {
			compatible = "espressif,esp32-timer"; /* in zephyr/dts/xtensa/espressif/esp32s3/esp32s3_common.dtsi:421 */
			reg = < 0x6001f024 0x1000 >;          /* in zephyr/dts/xtensa/espressif/esp32s3/esp32s3_common.dtsi:422 */
			clocks = < &rtc 0xa >;                /* in zephyr/dts/xtensa/espressif/esp32s3/esp32s3_common.dtsi:423 */
			group = < 0x0 >;                      /* in zephyr/dts/xtensa/espressif/esp32s3/esp32s3_common.dtsi:424 */
			index = < 0x1 >;                      /* in zephyr/dts/xtensa/espressif/esp32s3/esp32s3_common.dtsi:425 */
			interrupts = < 0x33 0x0 0x0 >;        /* in zephyr/dts/xtensa/espressif/esp32s3/esp32s3_common.dtsi:426 */
			interrupt-parent = < &intc >;         /* in zephyr/dts/xtensa/espressif/esp32s3/esp32s3_common.dtsi:427 */
			status = "disabled";                  /* in zephyr/boards/espressif/esp32s3_devkitc/esp32s3_devkitc_procpu.dts:128 */
		};

		/* node '/soc/counter@60020000' defined in zephyr/dts/xtensa/espressif/esp32s3/esp32s3_common.dtsi:431 */
		timer2: counter@60020000 {
			compatible = "espressif,esp32-timer"; /* in zephyr/dts/xtensa/espressif/esp32s3/esp32s3_common.dtsi:432 */
			reg = < 0x60020000 0x1000 >;          /* in zephyr/dts/xtensa/espressif/esp32s3/esp32s3_common.dtsi:433 */
			clocks = < &rtc 0xb >;                /* in zephyr/dts/xtensa/espressif/esp32s3/esp32s3_common.dtsi:434 */
			group = < 0x1 >;                      /* in zephyr/dts/xtensa/espressif/esp32s3/esp32s3_common.dtsi:435 */
			index = < 0x0 >;                      /* in zephyr/dts/xtensa/espressif/esp32s3/esp32s3_common.dtsi:436 */
			interrupts = < 0x35 0x0 0x0 >;        /* in zephyr/dts/xtensa/espressif/esp32s3/esp32s3_common.dtsi:437 */
			interrupt-parent = < &intc >;         /* in zephyr/dts/xtensa/espressif/esp32s3/esp32s3_common.dtsi:438 */
			status = "disabled";                  /* in zephyr/boards/espressif/esp32s3_devkitc/esp32s3_devkitc_procpu.dts:132 */
		};

		/* node '/soc/counter@60020024' defined in zephyr/dts/xtensa/espressif/esp32s3/esp32s3_common.dtsi:442 */
		timer3: counter@60020024 {
			compatible = "espressif,esp32-timer"; /* in zephyr/dts/xtensa/espressif/esp32s3/esp32s3_common.dtsi:443 */
			reg = < 0x60020024 0x1000 >;          /* in zephyr/dts/xtensa/espressif/esp32s3/esp32s3_common.dtsi:444 */
			clocks = < &rtc 0xb >;                /* in zephyr/dts/xtensa/espressif/esp32s3/esp32s3_common.dtsi:445 */
			group = < 0x1 >;                      /* in zephyr/dts/xtensa/espressif/esp32s3/esp32s3_common.dtsi:446 */
			index = < 0x1 >;                      /* in zephyr/dts/xtensa/espressif/esp32s3/esp32s3_common.dtsi:447 */
			interrupts = < 0x36 0x0 0x0 >;        /* in zephyr/dts/xtensa/espressif/esp32s3/esp32s3_common.dtsi:448 */
			interrupt-parent = < &intc >;         /* in zephyr/dts/xtensa/espressif/esp32s3/esp32s3_common.dtsi:449 */
			status = "disabled";                  /* in zephyr/boards/espressif/esp32s3_devkitc/esp32s3_devkitc_procpu.dts:136 */
		};

		/* node '/soc/watchdog@6001f048' defined in zephyr/dts/xtensa/espressif/esp32s3/esp32s3_common.dtsi:452 */
		wdt0: watchdog@6001f048 {
			compatible = "espressif,esp32-watchdog"; /* in zephyr/dts/xtensa/espressif/esp32s3/esp32s3_common.dtsi:453 */
			reg = < 0x6001f048 0x20 >;               /* in zephyr/dts/xtensa/espressif/esp32s3/esp32s3_common.dtsi:454 */
			interrupts = < 0x34 0x0 0x0 >;           /* in zephyr/dts/xtensa/espressif/esp32s3/esp32s3_common.dtsi:455 */
			interrupt-parent = < &intc >;            /* in zephyr/dts/xtensa/espressif/esp32s3/esp32s3_common.dtsi:456 */
			clocks = < &rtc 0xa >;                   /* in zephyr/dts/xtensa/espressif/esp32s3/esp32s3_common.dtsi:457 */
			status = "okay";                         /* in zephyr/boards/espressif/esp32s3_devkitc/esp32s3_devkitc_procpu.dts:140 */
		};

		/* node '/soc/watchdog@60020048' defined in zephyr/dts/xtensa/espressif/esp32s3/esp32s3_common.dtsi:461 */
		wdt1: watchdog@60020048 {
			compatible = "espressif,esp32-watchdog"; /* in zephyr/dts/xtensa/espressif/esp32s3/esp32s3_common.dtsi:462 */
			reg = < 0x60020048 0x20 >;               /* in zephyr/dts/xtensa/espressif/esp32s3/esp32s3_common.dtsi:463 */
			interrupts = < 0x37 0x0 0x0 >;           /* in zephyr/dts/xtensa/espressif/esp32s3/esp32s3_common.dtsi:464 */
			interrupt-parent = < &intc >;            /* in zephyr/dts/xtensa/espressif/esp32s3/esp32s3_common.dtsi:465 */
			clocks = < &rtc 0xb >;                   /* in zephyr/dts/xtensa/espressif/esp32s3/esp32s3_common.dtsi:466 */
			status = "disabled";                     /* in zephyr/dts/xtensa/espressif/esp32s3/esp32s3_common.dtsi:467 */
		};

		/* node '/soc/trng@6003507c' defined in zephyr/dts/xtensa/espressif/esp32s3/esp32s3_common.dtsi:470 */
		trng0: trng@6003507c {
			compatible = "espressif,esp32-trng"; /* in zephyr/dts/xtensa/espressif/esp32s3/esp32s3_common.dtsi:471 */
			reg = < 0x6003507c 0x4 >;            /* in zephyr/dts/xtensa/espressif/esp32s3/esp32s3_common.dtsi:472 */
			status = "okay";                     /* in zephyr/boards/espressif/esp32s3_devkitc/esp32s3_devkitc_procpu.dts:144 */
		};

		/* node '/soc/ledc@60019000' defined in zephyr/dts/xtensa/espressif/esp32s3/esp32s3_common.dtsi:476 */
		ledc0: ledc@60019000 {
			compatible = "espressif,esp32-ledc"; /* in zephyr/dts/xtensa/espressif/esp32s3/esp32s3_common.dtsi:477 */
			#pwm-cells = < 0x3 >;                /* in zephyr/dts/xtensa/espressif/esp32s3/esp32s3_common.dtsi:478 */
			reg = < 0x60019000 0x1000 >;         /* in zephyr/dts/xtensa/espressif/esp32s3/esp32s3_common.dtsi:479 */
			clocks = < &rtc 0x0 >;               /* in zephyr/dts/xtensa/espressif/esp32s3/esp32s3_common.dtsi:480 */
			status = "disabled";                 /* in zephyr/dts/xtensa/espressif/esp32s3/esp32s3_common.dtsi:481 */
		};

		/* node '/soc/mcpwm@6001e000' defined in zephyr/dts/xtensa/espressif/esp32s3/esp32s3_common.dtsi:484 */
		mcpwm0: mcpwm@6001e000 {
			compatible = "espressif,esp32-mcpwm"; /* in zephyr/dts/xtensa/espressif/esp32s3/esp32s3_common.dtsi:485 */
			reg = < 0x6001e000 0x1000 >;          /* in zephyr/dts/xtensa/espressif/esp32s3/esp32s3_common.dtsi:486 */
			interrupts = < 0x1f 0x0 0x0 >;        /* in zephyr/dts/xtensa/espressif/esp32s3/esp32s3_common.dtsi:487 */
			interrupt-parent = < &intc >;         /* in zephyr/dts/xtensa/espressif/esp32s3/esp32s3_common.dtsi:488 */
			clocks = < &rtc 0xc >;                /* in zephyr/dts/xtensa/espressif/esp32s3/esp32s3_common.dtsi:489 */
			#pwm-cells = < 0x3 >;                 /* in zephyr/dts/xtensa/espressif/esp32s3/esp32s3_common.dtsi:490 */
			status = "disabled";                  /* in zephyr/dts/xtensa/espressif/esp32s3/esp32s3_common.dtsi:491 */
		};

		/* node '/soc/mcpwm@6002c000' defined in zephyr/dts/xtensa/espressif/esp32s3/esp32s3_common.dtsi:494 */
		mcpwm1: mcpwm@6002c000 {
			compatible = "espressif,esp32-mcpwm"; /* in zephyr/dts/xtensa/espressif/esp32s3/esp32s3_common.dtsi:495 */
			reg = < 0x6002c000 0x1000 >;          /* in zephyr/dts/xtensa/espressif/esp32s3/esp32s3_common.dtsi:496 */
			interrupts = < 0x20 0x0 0x0 >;        /* in zephyr/dts/xtensa/espressif/esp32s3/esp32s3_common.dtsi:497 */
			interrupt-parent = < &intc >;         /* in zephyr/dts/xtensa/espressif/esp32s3/esp32s3_common.dtsi:498 */
			clocks = < &rtc 0xd >;                /* in zephyr/dts/xtensa/espressif/esp32s3/esp32s3_common.dtsi:499 */
			#pwm-cells = < 0x3 >;                 /* in zephyr/dts/xtensa/espressif/esp32s3/esp32s3_common.dtsi:500 */
			status = "disabled";                  /* in zephyr/dts/xtensa/espressif/esp32s3/esp32s3_common.dtsi:501 */
		};

		/* node '/soc/pcnt@60017000' defined in zephyr/dts/xtensa/espressif/esp32s3/esp32s3_common.dtsi:504 */
		pcnt: pcnt@60017000 {
			compatible = "espressif,esp32-pcnt"; /* in zephyr/dts/xtensa/espressif/esp32s3/esp32s3_common.dtsi:505 */
			reg = < 0x60017000 0x1000 >;         /* in zephyr/dts/xtensa/espressif/esp32s3/esp32s3_common.dtsi:506 */
			interrupts = < 0x29 0x0 0x0 >;       /* in zephyr/dts/xtensa/espressif/esp32s3/esp32s3_common.dtsi:507 */
			interrupt-parent = < &intc >;        /* in zephyr/dts/xtensa/espressif/esp32s3/esp32s3_common.dtsi:508 */
			clocks = < &rtc 0x13 >;              /* in zephyr/dts/xtensa/espressif/esp32s3/esp32s3_common.dtsi:509 */
			status = "disabled";                 /* in zephyr/dts/xtensa/espressif/esp32s3/esp32s3_common.dtsi:510 */
		};

		/* node '/soc/dma@6003f000' defined in zephyr/dts/xtensa/espressif/esp32s3/esp32s3_common.dtsi:513 */
		dma: dma@6003f000 {
			compatible = "espressif,esp32-gdma"; /* in zephyr/dts/xtensa/espressif/esp32s3/esp32s3_common.dtsi:514 */
			reg = < 0x6003f000 0x1000 >;         /* in zephyr/dts/xtensa/espressif/esp32s3/esp32s3_common.dtsi:515 */
			#dma-cells = < 0x1 >;                /* in zephyr/dts/xtensa/espressif/esp32s3/esp32s3_common.dtsi:516 */
			interrupts = < 0x42 0x0 0x100 >,
			             < 0x47 0x0 0x100 >,
			             < 0x43 0x0 0x100 >,
			             < 0x48 0x0 0x100 >,
			             < 0x44 0x0 0x100 >,
			             < 0x49 0x0 0x100 >,
			             < 0x45 0x0 0x100 >,
			             < 0x4a 0x0 0x100 >,
			             < 0x46 0x0 0x100 >,
			             < 0x4b 0x0 0x100 >;     /* in zephyr/dts/xtensa/espressif/esp32s3/esp32s3_common.dtsi:517 */
			interrupt-parent = < &intc >;        /* in zephyr/dts/xtensa/espressif/esp32s3/esp32s3_common.dtsi:528 */
			clocks = < &rtc 0x25 >;              /* in zephyr/dts/xtensa/espressif/esp32s3/esp32s3_common.dtsi:529 */
			dma-channels = < 0xa >;              /* in zephyr/dts/xtensa/espressif/esp32s3/esp32s3_common.dtsi:530 */
			dma-buf-addr-alignment = < 0x4 >;    /* in zephyr/dts/xtensa/espressif/esp32s3/esp32s3_common.dtsi:531 */
			status = "disabled";                 /* in zephyr/dts/xtensa/espressif/esp32s3/esp32s3_common.dtsi:532 */
			phandle = < 0x9 >;                   /* in zephyr/dts/xtensa/espressif/esp32s3/esp32s3_common.dtsi:313 */
		};

		/* node '/soc/sdhc@60028000' defined in zephyr/dts/xtensa/espressif/esp32s3/esp32s3_common.dtsi:535 */
		sdhc: sdhc@60028000 {
			compatible = "espressif,esp32-sdhc"; /* in zephyr/dts/xtensa/espressif/esp32s3/esp32s3_common.dtsi:536 */
			reg = < 0x60028000 0x1000 >;         /* in zephyr/dts/xtensa/espressif/esp32s3/esp32s3_common.dtsi:537 */
			interrupts = < 0x1e 0x0 0x0 >;       /* in zephyr/dts/xtensa/espressif/esp32s3/esp32s3_common.dtsi:538 */
			interrupt-parent = < &intc >;        /* in zephyr/dts/xtensa/espressif/esp32s3/esp32s3_common.dtsi:539 */
			clocks = < &rtc 0x17 >;              /* in zephyr/dts/xtensa/espressif/esp32s3/esp32s3_common.dtsi:540 */
			#address-cells = < 0x1 >;            /* in zephyr/dts/xtensa/espressif/esp32s3/esp32s3_common.dtsi:541 */
			#size-cells = < 0x0 >;               /* in zephyr/dts/xtensa/espressif/esp32s3/esp32s3_common.dtsi:542 */

			/* node '/soc/sdhc@60028000/sdhc@0' defined in zephyr/dts/xtensa/espressif/esp32s3/esp32s3_common.dtsi:544 */
			sdhc0: sdhc@0 {
				compatible = "espressif,esp32-sdhc-slot"; /* in zephyr/dts/xtensa/espressif/esp32s3/esp32s3_common.dtsi:545 */
				reg = < 0x0 >;                            /* in zephyr/dts/xtensa/espressif/esp32s3/esp32s3_common.dtsi:546 */
				status = "disabled";                      /* in zephyr/dts/xtensa/espressif/esp32s3/esp32s3_common.dtsi:547 */
			};

			/* node '/soc/sdhc@60028000/sdhc@1' defined in zephyr/dts/xtensa/espressif/esp32s3/esp32s3_common.dtsi:550 */
			sdhc1: sdhc@1 {
				compatible = "espressif,esp32-sdhc-slot"; /* in zephyr/dts/xtensa/espressif/esp32s3/esp32s3_common.dtsi:551 */
				reg = < 0x1 >;                            /* in zephyr/dts/xtensa/espressif/esp32s3/esp32s3_common.dtsi:552 */
				status = "disabled";                      /* in zephyr/dts/xtensa/espressif/esp32s3/esp32s3_common.dtsi:553 */
			};
		};
	};

	/* node '/cpus' defined in zephyr/dts/xtensa/espressif/esp32s3/esp32s3_common.dtsi:28 */
	cpus {
		#address-cells = < 0x1 >; /* in zephyr/dts/xtensa/espressif/esp32s3/esp32s3_common.dtsi:29 */
		#size-cells = < 0x0 >;    /* in zephyr/dts/xtensa/espressif/esp32s3/esp32s3_common.dtsi:30 */

		/* node '/cpus/cpu@0' defined in zephyr/dts/xtensa/espressif/esp32s3/esp32s3_common.dtsi:32 */
		cpu0: cpu@0 {
			device_type = "cpu";                             /* in zephyr/dts/xtensa/espressif/esp32s3/esp32s3_common.dtsi:33 */
			compatible = "espressif,xtensa-lx7";             /* in zephyr/dts/xtensa/espressif/esp32s3/esp32s3_common.dtsi:34 */
			reg = < 0x0 >;                                   /* in zephyr/dts/xtensa/espressif/esp32s3/esp32s3_common.dtsi:35 */
			cpu-power-states = < &light_sleep &deep_sleep >; /* in zephyr/dts/xtensa/espressif/esp32s3/esp32s3_common.dtsi:36 */
			clock-source = < 0x1 >;                          /* in zephyr/dts/xtensa/espressif/esp32s3/esp32s3_common.dtsi:37 */
			clock-frequency = < 0xe4e1c00 >;                 /* in zephyr/dts/xtensa/espressif/esp32s3/esp32s3_common.dtsi:38 */
			xtal-freq = < 0x2625a00 >;                       /* in zephyr/dts/xtensa/espressif/esp32s3/esp32s3_common.dtsi:39 */
		};

		/* node '/cpus/cpu@1' defined in zephyr/dts/xtensa/espressif/esp32s3/esp32s3_common.dtsi:42 */
		cpu1: cpu@1 {
			device_type = "cpu";                 /* in zephyr/dts/xtensa/espressif/esp32s3/esp32s3_common.dtsi:43 */
			compatible = "espressif,xtensa-lx7"; /* in zephyr/dts/xtensa/espressif/esp32s3/esp32s3_common.dtsi:44 */
			reg = < 0x1 >;                       /* in zephyr/dts/xtensa/espressif/esp32s3/esp32s3_common.dtsi:45 */
			clock-source = < 0x1 >;              /* in zephyr/dts/xtensa/espressif/esp32s3/esp32s3_common.dtsi:46 */
			clock-frequency = < 0xe4e1c00 >;     /* in zephyr/dts/xtensa/espressif/esp32s3/esp32s3_common.dtsi:47 */
			xtal-freq = < 0x2625a00 >;           /* in zephyr/dts/xtensa/espressif/esp32s3/esp32s3_common.dtsi:48 */
		};

		/* node '/cpus/power-states' defined in zephyr/dts/xtensa/espressif/esp32s3/esp32s3_common.dtsi:51 */
		power-states {

			/* node '/cpus/power-states/light_sleep' defined in zephyr/dts/xtensa/espressif/esp32s3/esp32s3_common.dtsi:52 */
			light_sleep: light_sleep {
				compatible = "zephyr,power-state"; /* in zephyr/dts/xtensa/espressif/esp32s3/esp32s3_common.dtsi:53 */
				power-state-name = "standby";      /* in zephyr/dts/xtensa/espressif/esp32s3/esp32s3_common.dtsi:54 */
				min-residency-us = < 0xc8 >;       /* in zephyr/dts/xtensa/espressif/esp32s3/esp32s3_common.dtsi:55 */
				exit-latency-us = < 0x85 >;        /* in zephyr/dts/xtensa/espressif/esp32s3/esp32s3_common.dtsi:56 */
				phandle = < 0xf >;                 /* in zephyr/dts/xtensa/espressif/esp32s3/esp32s3_common.dtsi:36 */
			};

			/* node '/cpus/power-states/deep_sleep' defined in zephyr/dts/xtensa/espressif/esp32s3/esp32s3_common.dtsi:59 */
			deep_sleep: deep_sleep {
				compatible = "zephyr,power-state"; /* in zephyr/dts/xtensa/espressif/esp32s3/esp32s3_common.dtsi:60 */
				power-state-name = "soft-off";     /* in zephyr/dts/xtensa/espressif/esp32s3/esp32s3_common.dtsi:61 */
				min-residency-us = < 0x7d0 >;      /* in zephyr/dts/xtensa/espressif/esp32s3/esp32s3_common.dtsi:62 */
				exit-latency-us = < 0x17e >;       /* in zephyr/dts/xtensa/espressif/esp32s3/esp32s3_common.dtsi:63 */
				phandle = < 0x10 >;                /* in zephyr/dts/xtensa/espressif/esp32s3/esp32s3_common.dtsi:36 */
			};
		};
	};

	/* node '/wifi' defined in zephyr/dts/xtensa/espressif/esp32s3/esp32s3_common.dtsi:68 */
	wifi: wifi {
		compatible = "espressif,esp32-wifi"; /* in zephyr/dts/xtensa/espressif/esp32s3/esp32s3_common.dtsi:69 */
		status = "okay";                     /* in zephyr/boards/espressif/esp32s3_devkitc/esp32s3_devkitc_procpu.dts:152 */
	};

	/* node '/esp32_bt_hci' defined in zephyr/dts/xtensa/espressif/esp32s3/esp32s3_common.dtsi:73 */
	esp32_bt_hci: esp32_bt_hci {
		compatible = "espressif,esp32-bt-hci"; /* in zephyr/dts/xtensa/espressif/esp32s3/esp32s3_common.dtsi:74 */
		status = "okay";                       /* in zephyr/boards/espressif/esp32s3_devkitc/esp32s3_devkitc_procpu.dts:148 */
	};

	/* node '/pin-controller' defined in zephyr/dts/xtensa/espressif/esp32s3/esp32s3_common.dtsi:78 */
	pinctrl: pin-controller {
		compatible = "espressif,esp32-pinctrl"; /* in zephyr/dts/xtensa/espressif/esp32s3/esp32s3_common.dtsi:79 */
		status = "okay";                        /* in zephyr/dts/xtensa/espressif/esp32s3/esp32s3_common.dtsi:80 */

		/* node '/pin-controller/uart0_default' defined in zephyr/boards/espressif/esp32s3_devkitc/esp32s3_devkitc-pinctrl.dtsi:12 */
		uart0_default: uart0_default {
			phandle = < 0x4 >; /* in zephyr/boards/espressif/esp32s3_devkitc/esp32s3_devkitc_procpu.dts:54 */

			/* node '/pin-controller/uart0_default/group1' defined in zephyr/boards/espressif/esp32s3_devkitc/esp32s3_devkitc-pinctrl.dtsi:13 */
			group1 {
				pinmux = < 0x67feb >; /* in zephyr/boards/espressif/esp32s3_devkitc/esp32s3_devkitc-pinctrl.dtsi:14 */
				output-high;          /* in zephyr/boards/espressif/esp32s3_devkitc/esp32s3_devkitc-pinctrl.dtsi:15 */
			};

			/* node '/pin-controller/uart0_default/group2' defined in zephyr/boards/espressif/esp32s3_devkitc/esp32s3_devkitc-pinctrl.dtsi:17 */
			group2 {
				pinmux = < 0xff832c >; /* in zephyr/boards/espressif/esp32s3_devkitc/esp32s3_devkitc-pinctrl.dtsi:18 */
				bias-pull-up;          /* in zephyr/boards/espressif/esp32s3_devkitc/esp32s3_devkitc-pinctrl.dtsi:19 */
			};
		};

		/* node '/pin-controller/uart1_default' defined in zephyr/boards/espressif/esp32s3_devkitc/esp32s3_devkitc-pinctrl.dtsi:23 */
		uart1_default: uart1_default {

			/* node '/pin-controller/uart1_default/group1' defined in zephyr/boards/espressif/esp32s3_devkitc/esp32s3_devkitc-pinctrl.dtsi:24 */
			group1 {
				pinmux = < 0x7ffd1 >; /* in zephyr/boards/espressif/esp32s3_devkitc/esp32s3_devkitc-pinctrl.dtsi:25 */
				output-high;          /* in zephyr/boards/espressif/esp32s3_devkitc/esp32s3_devkitc-pinctrl.dtsi:26 */
			};

			/* node '/pin-controller/uart1_default/group2' defined in zephyr/boards/espressif/esp32s3_devkitc/esp32s3_devkitc-pinctrl.dtsi:28 */
			group2 {
				pinmux = < 0xff83d2 >; /* in zephyr/boards/espressif/esp32s3_devkitc/esp32s3_devkitc-pinctrl.dtsi:29 */
				bias-pull-up;          /* in zephyr/boards/espressif/esp32s3_devkitc/esp32s3_devkitc-pinctrl.dtsi:30 */
			};
		};

		/* node '/pin-controller/i2c0_default' defined in zephyr/boards/espressif/esp32s3_devkitc/esp32s3_devkitc-pinctrl.dtsi:34 */
		i2c0_default: i2c0_default {
			phandle = < 0x7 >; /* in zephyr/boards/espressif/esp32s3_devkitc/esp32s3_devkitc_procpu.dts:80 */

			/* node '/pin-controller/i2c0_default/group1' defined in zephyr/boards/espressif/esp32s3_devkitc/esp32s3_devkitc-pinctrl.dtsi:35 */
			group1 {
				pinmux = < 0x2d1681 >,
				         < 0x2c9642 >; /* in zephyr/boards/espressif/esp32s3_devkitc/esp32s3_devkitc-pinctrl.dtsi:36 */
				bias-pull-up;          /* in zephyr/boards/espressif/esp32s3_devkitc/esp32s3_devkitc-pinctrl.dtsi:38 */
				drive-open-drain;      /* in zephyr/boards/espressif/esp32s3_devkitc/esp32s3_devkitc-pinctrl.dtsi:39 */
				output-high;           /* in zephyr/boards/espressif/esp32s3_devkitc/esp32s3_devkitc-pinctrl.dtsi:40 */
			};
		};

		/* node '/pin-controller/i2c1_default' defined in zephyr/boards/espressif/esp32s3_devkitc/esp32s3_devkitc-pinctrl.dtsi:44 */
		i2c1_default: i2c1_default {
			phandle = < 0x8 >; /* in zephyr/boards/espressif/esp32s3_devkitc/esp32s3_devkitc_procpu.dts:86 */

			/* node '/pin-controller/i2c1_default/group1' defined in zephyr/boards/espressif/esp32s3_devkitc/esp32s3_devkitc-pinctrl.dtsi:45 */
			group1 {
				pinmux = < 0x2e1704 >,
				         < 0x2d96c5 >; /* in zephyr/boards/espressif/esp32s3_devkitc/esp32s3_devkitc-pinctrl.dtsi:46 */
				bias-pull-up;          /* in zephyr/boards/espressif/esp32s3_devkitc/esp32s3_devkitc-pinctrl.dtsi:48 */
				drive-open-drain;      /* in zephyr/boards/espressif/esp32s3_devkitc/esp32s3_devkitc-pinctrl.dtsi:49 */
				output-high;           /* in zephyr/boards/espressif/esp32s3_devkitc/esp32s3_devkitc-pinctrl.dtsi:50 */
			};
		};

		/* node '/pin-controller/i2s0_default' defined in zephyr/boards/espressif/esp32s3_devkitc/esp32s3_devkitc-pinctrl.dtsi:54 */
		i2s0_default: i2s0_default {
			phandle = < 0xa >; /* in zephyr/boards/espressif/esp32s3_devkitc/esp32s3_devkitc_procpu.dts:91 */

			/* node '/pin-controller/i2s0_default/group1' defined in zephyr/boards/espressif/esp32s3_devkitc/esp32s3_devkitc-pinctrl.dtsi:55 */
			group1 {
				pinmux = < 0xbffc4 >,
				         < 0xc0605 >,
				         < 0xb0586 >,
				         < 0xcffc7 >,
				         < 0xd86cf >,
				         < 0xd0690 >; /* in zephyr/boards/espressif/esp32s3_devkitc/esp32s3_devkitc-pinctrl.dtsi:56 */
				output-enable;        /* in zephyr/boards/espressif/esp32s3_devkitc/esp32s3_devkitc-pinctrl.dtsi:62 */
			};

			/* node '/pin-controller/i2s0_default/group2' defined in zephyr/boards/espressif/esp32s3_devkitc/esp32s3_devkitc-pinctrl.dtsi:64 */
			group2 {
				pinmux = < 0xff8651 >; /* in zephyr/boards/espressif/esp32s3_devkitc/esp32s3_devkitc-pinctrl.dtsi:65 */
				input-enable;          /* in zephyr/boards/espressif/esp32s3_devkitc/esp32s3_devkitc-pinctrl.dtsi:66 */
			};
		};

		/* node '/pin-controller/i2s1_default' defined in zephyr/boards/espressif/esp32s3_devkitc/esp32s3_devkitc-pinctrl.dtsi:70 */
		i2s1_default: i2s1_default {
			phandle = < 0xb >; /* in zephyr/boards/espressif/esp32s3_devkitc/esp32s3_devkitc_procpu.dts:97 */

			/* node '/pin-controller/i2s1_default/group1' defined in zephyr/boards/espressif/esp32s3_devkitc/esp32s3_devkitc-pinctrl.dtsi:71 */
			group1 {
				pinmux = < 0xaffd2 >,
				         < 0xe8748 >,
				         < 0xe0703 >,
				         < 0xf7fc9 >,
				         < 0x10080a >,
				         < 0xf87cb >;  /* in zephyr/boards/espressif/esp32s3_devkitc/esp32s3_devkitc-pinctrl.dtsi:72 */
				output-enable;         /* in zephyr/boards/espressif/esp32s3_devkitc/esp32s3_devkitc-pinctrl.dtsi:78 */
			};

			/* node '/pin-controller/i2s1_default/group2' defined in zephyr/boards/espressif/esp32s3_devkitc/esp32s3_devkitc-pinctrl.dtsi:80 */
			group2 {
				pinmux = < 0xff878c >; /* in zephyr/boards/espressif/esp32s3_devkitc/esp32s3_devkitc-pinctrl.dtsi:81 */
				input-enable;          /* in zephyr/boards/espressif/esp32s3_devkitc/esp32s3_devkitc-pinctrl.dtsi:82 */
			};
		};

		/* node '/pin-controller/spim2_default' defined in zephyr/boards/espressif/esp32s3_devkitc/esp32s3_devkitc-pinctrl.dtsi:86 */
		spim2_default: spim2_default {
			phandle = < 0xc >; /* in zephyr/boards/espressif/esp32s3_devkitc/esp32s3_devkitc_procpu.dts:106 */

			/* node '/pin-controller/spim2_default/group1' defined in zephyr/boards/espressif/esp32s3_devkitc/esp32s3_devkitc-pinctrl.dtsi:87 */
			group1 {
				pinmux = < 0xff998d >,
				         < 0x32ffcc >,
				         < 0x377fca >; /* in zephyr/boards/espressif/esp32s3_devkitc/esp32s3_devkitc-pinctrl.dtsi:88 */
			};

			/* node '/pin-controller/spim2_default/group2' defined in zephyr/boards/espressif/esp32s3_devkitc/esp32s3_devkitc-pinctrl.dtsi:92 */
			group2 {
				pinmux = < 0x33ffcb >; /* in zephyr/boards/espressif/esp32s3_devkitc/esp32s3_devkitc-pinctrl.dtsi:93 */
				output-low;            /* in zephyr/boards/espressif/esp32s3_devkitc/esp32s3_devkitc-pinctrl.dtsi:94 */
			};
		};

		/* node '/pin-controller/spim3_default' defined in zephyr/boards/espressif/esp32s3_devkitc/esp32s3_devkitc-pinctrl.dtsi:98 */
		spim3_default: spim3_default {
			phandle = < 0xd >; /* in zephyr/boards/espressif/esp32s3_devkitc/esp32s3_devkitc_procpu.dts:114 */

			/* node '/pin-controller/spim3_default/group1' defined in zephyr/boards/espressif/esp32s3_devkitc/esp32s3_devkitc-pinctrl.dtsi:99 */
			group1 {
				pinmux = < 0xff90e5 >,
				         < 0x217fe4 >,
				         < 0x23ffe6 >; /* in zephyr/boards/espressif/esp32s3_devkitc/esp32s3_devkitc-pinctrl.dtsi:100 */
			};

			/* node '/pin-controller/spim3_default/group2' defined in zephyr/boards/espressif/esp32s3_devkitc/esp32s3_devkitc-pinctrl.dtsi:104 */
			group2 {
				pinmux = < 0x227fe7 >; /* in zephyr/boards/espressif/esp32s3_devkitc/esp32s3_devkitc-pinctrl.dtsi:105 */
				output-low;            /* in zephyr/boards/espressif/esp32s3_devkitc/esp32s3_devkitc-pinctrl.dtsi:106 */
			};
		};

		/* node '/pin-controller/twai_default' defined in zephyr/boards/espressif/esp32s3_devkitc/esp32s3_devkitc-pinctrl.dtsi:110 */
		twai_default: twai_default {
			phandle = < 0xe >; /* in zephyr/boards/espressif/esp32s3_devkitc/esp32s3_devkitc_procpu.dts:119 */

			/* node '/pin-controller/twai_default/group1' defined in zephyr/boards/espressif/esp32s3_devkitc/esp32s3_devkitc-pinctrl.dtsi:111 */
			group1 {
				pinmux = < 0x3a7fc5 >,
				         < 0xff9d06 >; /* in zephyr/boards/espressif/esp32s3_devkitc/esp32s3_devkitc-pinctrl.dtsi:112 */
			};
		};
	};

	/* node '/buttons' defined in zephyr/boards/espressif/esp32s3_devkitc/esp32s3_devkitc_procpu.dts:37 */
	buttons {
		compatible = "gpio-keys"; /* in zephyr/boards/espressif/esp32s3_devkitc/esp32s3_devkitc_procpu.dts:38 */

		/* node '/buttons/button_0' defined in zephyr/boards/espressif/esp32s3_devkitc/esp32s3_devkitc_procpu.dts:39 */
		button0: button_0 {
			gpios = < &gpio0 0x0 0x11 >; /* in zephyr/boards/espressif/esp32s3_devkitc/esp32s3_devkitc_procpu.dts:40 */
			label = "BOOT Button";       /* in zephyr/boards/espressif/esp32s3_devkitc/esp32s3_devkitc_procpu.dts:41 */
			zephyr,code = < 0xb >;       /* in zephyr/boards/espressif/esp32s3_devkitc/esp32s3_devkitc_procpu.dts:42 */
		};
	};
};
